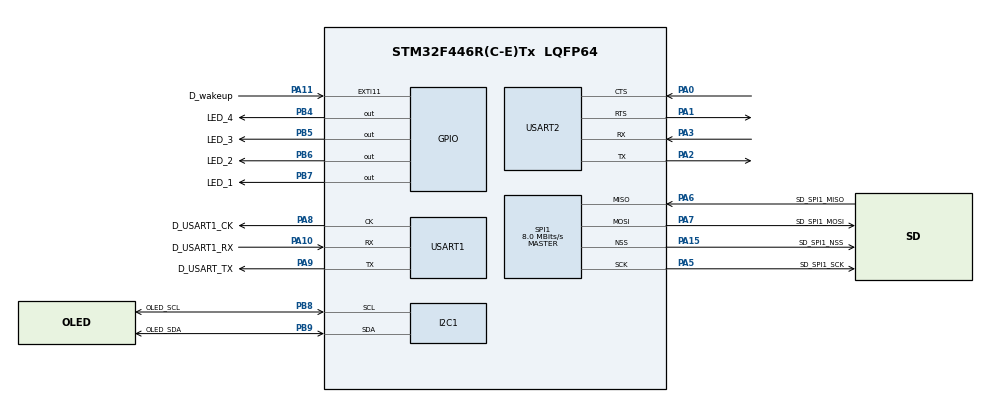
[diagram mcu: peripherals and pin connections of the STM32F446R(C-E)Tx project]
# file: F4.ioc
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Mcu.Family=STM32F4
Mcu.Name=STM32F446R(C-E)Tx
Mcu.Package=LQFP64
NVIC.PriorityGroup=NVIC_PRIORITYGROUP_4
PA0-WKUP.Mode=CTS_RTS
PA0-WKUP.Signal=USART2_CTS
PA1.Mode=CTS_RTS
PA1.Signal=USART2_RTS
PA10.GPIO_Label=D_USART1_RX
PA10.Mode=Synchronous
PA10.Signal=USART1_RX
PA11.GPIO_Label=D_wakeup
PA11.Signal=GPXTI11
PA13.Mode=Serial_Wire
PA13.Signal=SYS_JTMS-SWDIO
PA14.Mode=Serial_Wire
PA14.Signal=SYS_JTCK-SWCLK
PA15.GPIO_Label=SD_SPI1_NSS
PA15.Mode=NSS_Signal_Hard_Output
PA15.Signal=SPI1_NSS
PA2.Mode=Asynchronous
PA2.Signal=USART2_TX
PA3.Mode=Asynchronous
PA3.Signal=USART2_RX
PA5.GPIO_Label=SD_SPI1_SCK
PA5.Mode=Full_Duplex_Master
PA5.Signal=SPI1_SCK
PA6.GPIO_Label=SD_SPI1_MISO
PA6.Mode=Full_Duplex_Master
PA6.Signal=SPI1_MISO
PA7.GPIO_Label=SD_SPI1_MOSI
PA7.Mode=Full_Duplex_Master
PA7.Signal=SPI1_MOSI
PA8.GPIO_Label=D_USART1_CK
PA8.Mode=Synchronous
PA8.Signal=USART1_CK
PA9.GPIO_Label=D_USART_TX
PA9.Mode=Synchronous
PA9.Signal=USART1_TX
PB4.GPIO_Label=LED_4
PB4.Signal=GPIO_Output
PB5.GPIO_Label=LED_3
PB5.Signal=GPIO_Output
PB6.GPIO_Label=LED_2
PB6.Signal=GPIO_Output
PB7.GPIO_Label=LED_1
PB7.Signal=GPIO_Output
PB8.GPIO_Label=OLED_SCL
PB8.Mode=I2C
PB8.Signal=I2C1_SCL
PB9.GPIO_Label=OLED_SDA
PB9.Mode=I2C
PB9.Signal=I2C1_SDA
PH0-OSC_IN.Mode=HSE-External-Oscillator
PH0-OSC_IN.Signal=RCC_OSC_IN
PH1-OSC_OUT.Mode=HSE-External-Oscillator
PH1-OSC_OUT.Signal=RCC_OSC_OUT
ProjectManager.HeapSize=0x200
ProjectManager.StackSize=0x400
ProjectManager.TargetToolchain=STM32CubeIDE
RCC.CortexFreq_Value=16000000
RCC.USBFreq_Value=96000000
RCC.VCOOutputFreq_Value=192000000
SPI1.CalculateBaudRate=8.0 MBits/s
SPI1.Direction=SPI_DIRECTION_2LINES
SPI1.Mode=SPI_MODE_MASTER
SPI1.VirtualNSS=VM_NSSHARD
SPI1.VirtualType=VM_MASTER
USART1.VirtualMode=VM_SYNC
USART2.VirtualMode=VM_ASYNC
board=custom

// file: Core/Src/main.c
/* USER CODE BEGIN Header */
/**
  ******************************************************************************
  * @file           : main.c
  * @brief          : Main program body
  ******************************************************************************
  * @attention
  *
  * Copyright (c) 2026 STMicroelectronics.
  * All rights reserved.
  *
  * This software is licensed under terms that can be found in the LICENSE file
  * in the root directory of this software component.
  * If no LICENSE file comes with this software, it is provided AS-IS.
  *
  ******************************************************************************
  */
/* USER CODE END Header */
#include "main.h"
#include "i2c.h"
#include "spi.h"
#include "usart.h"
#include "gpio.h"

/* USER CODE BEGIN Includes */
// OLED LIbraries:
#include "ssd1306.h"
#include "ssd1306_fonts.h"
/* USER CODE END Includes */

void SystemClock_Config(void);

int main(void)
{

  /* MCU Configuration--------------------------------------------------------*/

  /* Reset of all peripherals, Initializes the Flash interface and the Systick. */
  HAL_Init();

  /* Configure the system clock */
  SystemClock_Config();

  /* Initialize all configured peripherals */
  MX_GPIO_Init();
  MX_USART1_Init();
  MX_SPI1_Init();
  MX_USART2_UART_Init();
  MX_I2C1_Init();
  /* USER CODE BEGIN 2 */

  // Initialise the OLED
  ssd1306_Init();

  // Clear Buffer and write text
  ssd1306_Fill(Black);
  ssd1306_SetCursor(2, 5);
  ssd1306_WriteString("STM32 ONLINE", Font_7x10, White);

  // Update screen
  ssd1306_UpdateScreen();

  /* USER CODE END 2 */

  /* Infinite loop */
  /* USER CODE BEGIN WHILE */
  while (1)
  {
	  HAL_GPIO_TogglePin(GPIOB, LED_4_Pin | LED_3_Pin | LED_2_Pin | LED_1_Pin);
	  HAL_Delay(1000);
    /* USER CODE END WHILE */

  }
}

void SystemClock_Config(void)
{
  RCC_OscInitTypeDef RCC_OscInitStruct = {0};
  RCC_ClkInitTypeDef RCC_ClkInitStruct = {0};

  /** Configure the main internal regulator output voltage
  */
  __HAL_RCC_PWR_CLK_ENABLE();
  __HAL_PWR_VOLTAGESCALING_CONFIG(PWR_REGULATOR_VOLTAGE_SCALE3);

  /** Initializes the RCC Oscillators according to the specified parameters
  * in the RCC_OscInitTypeDef structure.
  */
  RCC_OscInitStruct.OscillatorType = RCC_OSCILLATORTYPE_HSI;
  RCC_OscInitStruct.HSIState = RCC_HSI_ON;
  RCC_OscInitStruct.HSICalibrationValue = RCC_HSICALIBRATION_DEFAULT;
  RCC_OscInitStruct.PLL.PLLState = RCC_PLL_NONE;
  if (HAL_RCC_OscConfig(&RCC_OscInitStruct) != HAL_OK)
  {
    Error_Handler();
  }

  /** Initializes the CPU, AHB and APB buses clocks
  */
  RCC_ClkInitStruct.ClockType = RCC_CLOCKTYPE_HCLK|RCC_CLOCKTYPE_SYSCLK
                              |RCC_CLOCKTYPE_PCLK1|RCC_CLOCKTYPE_PCLK2;
  RCC_ClkInitStruct.SYSCLKSource = RCC_SYSCLKSOURCE_HSI;
  RCC_ClkInitStruct.AHBCLKDivider = RCC_SYSCLK_DIV1;
  RCC_ClkInitStruct.APB1CLKDivider = RCC_HCLK_DIV1;
  RCC_ClkInitStruct.APB2CLKDivider = RCC_HCLK_DIV1;

  if (HAL_RCC_ClockConfig(&RCC_ClkInitStruct, FLASH_LATENCY_0) != HAL_OK)
  {
    Error_Handler();
  }
}

void Error_Handler(void)
{
  __disable_irq();
  while (1)
  {
  }
}
